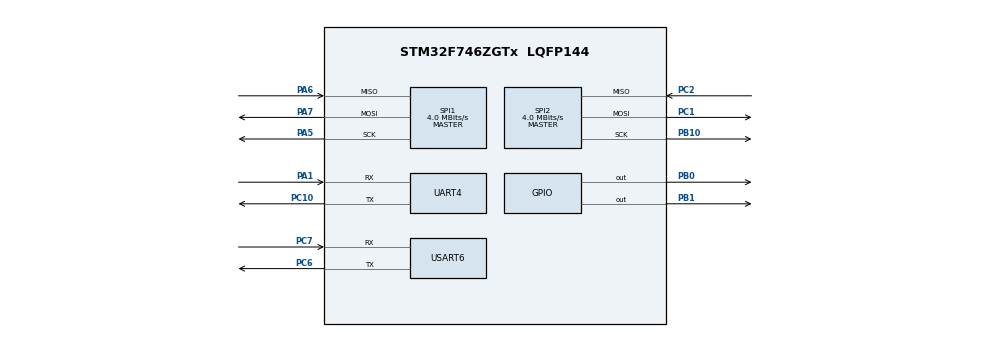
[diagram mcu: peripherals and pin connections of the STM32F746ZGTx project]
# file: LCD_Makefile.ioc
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Mcu.Family=STM32F7
Mcu.Name=STM32F746ZGTx
Mcu.Package=LQFP144
NVIC.PriorityGroup=NVIC_PRIORITYGROUP_4
PA0/WKUP.Mode=SYS_WakeUp0
PA0/WKUP.Signal=SYS_WKUP1
PA1.Mode=Asynchronous
PA1.Signal=UART4_RX
PA13.Signal=SYS_JTMS-SWDIO
PA14.Signal=SYS_JTCK-SWCLK
PA5.Mode=Full_Duplex_Master
PA5.Signal=SPI1_SCK
PA6.Mode=Full_Duplex_Master
PA6.Signal=SPI1_MISO
PA7.Mode=Full_Duplex_Master
PA7.Signal=SPI1_MOSI
PB0.Signal=GPIO_Output
PB1.Signal=GPIO_Output
PB10.Mode=Full_Duplex_Master
PB10.Signal=SPI2_SCK
PB3.Signal=SYS_JTDO-SWO
PC1.Mode=Full_Duplex_Master
PC1.Signal=SPI2_MOSI
PC10.Mode=Asynchronous
PC10.Signal=UART4_TX
PC2.Mode=Full_Duplex_Master
PC2.Signal=SPI2_MISO
PC6.Mode=Asynchronous
PC6.Signal=USART6_TX
PC7.Mode=Asynchronous
PC7.Signal=USART6_RX
ProjectManager.HeapSize=0x200
ProjectManager.StackSize=0x400
ProjectManager.TargetToolchain=SW4STM32
RCC.AHBCLKDivider=RCC_SYSCLK_DIV2
RCC.AHBFreq_Value=8000000
RCC.APB1Freq_Value=8000000
RCC.APB1TimFreq_Value=8000000
RCC.APB2Freq_Value=8000000
RCC.APB2TimFreq_Value=8000000
RCC.CortexFreq_Value=8000000
RCC.HCLKFreq_Value=8000000
RCC.HSE_VALUE=25000000
RCC.HSI_VALUE=16000000
RCC.LSE_VALUE=32768
RCC.USBFreq_Value=96000000
RCC.VCOOutputFreq_Value=192000000
SPI1.BaudRatePrescaler=SPI_BAUDRATEPRESCALER_2
SPI1.CLKPhase=SPI_PHASE_1EDGE
SPI1.CLKPolarity=SPI_POLARITY_LOW
SPI1.CalculateBaudRate=4.0 MBits/s
SPI1.DataSize=SPI_DATASIZE_8BIT
SPI1.Direction=SPI_DIRECTION_2LINES
SPI1.Mode=SPI_MODE_MASTER
SPI1.NSSPMode=SPI_NSS_PULSE_DISABLE
SPI1.VirtualType=VM_MASTER
SPI2.CalculateBaudRate=4.0 MBits/s
SPI2.DataSize=SPI_DATASIZE_8BIT
SPI2.Direction=SPI_DIRECTION_2LINES
SPI2.Mode=SPI_MODE_MASTER
SPI2.VirtualType=VM_MASTER
USART6.VirtualMode-Asynchronous=VM_ASYNC
board=custom

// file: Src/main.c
/* USER CODE BEGIN Header */
/**
  ******************************************************************************
  * @file           : main.c
  * @brief          : Main program body
  ******************************************************************************
  ** This notice applies to any and all portions of this file
  * that are not between comment pairs USER CODE BEGIN and
  * USER CODE END. Other portions of this file, whether
  * inserted by the user or by software development tools
  * are owned by their respective copyright owners.
  *
  * COPYRIGHT(c) 2019 STMicroelectronics
  *
  * Redistribution and use in source and binary forms, with or without modification,
  * are permitted provided that the following conditions are met:
  *   1. Redistributions of source code must retain the above copyright notice,
  *      this list of conditions and the following disclaimer.
  *   2. Redistributions in binary form must reproduce the above copyright notice,
  *      this list of conditions and the following disclaimer in the documentation
  *      and/or other materials provided with the distribution.
  *   3. Neither the name of STMicroelectronics nor the names of its contributors
  *      may be used to endorse or promote products derived from this software
  *      without specific prior written permission.
  *
  * THIS SOFTWARE IS PROVIDED BY THE COPYRIGHT HOLDERS AND CONTRIBUTORS "AS IS"
  * AND ANY EXPRESS OR IMPLIED WARRANTIES, INCLUDING, BUT NOT LIMITED TO, THE
  * IMPLIED WARRANTIES OF MERCHANTABILITY AND FITNESS FOR A PARTICULAR PURPOSE ARE
  * DISCLAIMED. IN NO EVENT SHALL THE COPYRIGHT HOLDER OR CONTRIBUTORS BE LIABLE
  * FOR ANY DIRECT, INDIRECT, INCIDENTAL, SPECIAL, EXEMPLARY, OR CONSEQUENTIAL
  * DAMAGES (INCLUDING, BUT NOT LIMITED TO, PROCUREMENT OF SUBSTITUTE GOODS OR
  * SERVICES; LOSS OF USE, DATA, OR PROFITS; OR BUSINESS INTERRUPTION) HOWEVER
  * CAUSED AND ON ANY THEORY OF LIABILITY, WHETHER IN CONTRACT, STRICT LIABILITY,
  * OR TORT (INCLUDING NEGLIGENCE OR OTHERWISE) ARISING IN ANY WAY OUT OF THE USE
  * OF THIS SOFTWARE, EVEN IF ADVISED OF THE POSSIBILITY OF SUCH DAMAGE.
  *
  ******************************************************************************
  */
/* USER CODE END Header */

#include "main.h"

/* USER CODE BEGIN Includes */
#include "FT_Platform.h"
#include "Ft_Esd.h"
#include "Ft_Esd_GpuAlloc.h"
/* USER CODE END Includes */

SPI_HandleTypeDef hspi1;
SPI_HandleTypeDef hspi2;

UART_HandleTypeDef huart4;
UART_HandleTypeDef huart6;

void SystemClock_Config(void);
static void MX_GPIO_Init(void);
static void MX_SPI1_Init(void);
static void MX_SPI2_Init(void);
static void MX_UART4_Init(void);
static void MX_USART6_UART_Init(void);
/* USER CODE BEGIN PFP */
extern ft_void_t FT800_BootupConfig();
/* USER CODE END PFP */

int main(void)
{

  /* MCU Configuration--------------------------------------------------------*/

  /* Reset of all peripherals, Initializes the Flash interface and the Systick. */
  HAL_Init();

  /* Configure the system clock */
  SystemClock_Config();

  /* Initialize all configured peripherals */
  MX_GPIO_Init();
  MX_SPI1_Init();
  MX_SPI2_Init();
  MX_UART4_Init();
  MX_USART6_UART_Init();
  /* USER CODE BEGIN 2 */
  FT800_BootupConfig();
  /* USER CODE END 2 */

  /* Infinite loop */
  while (1)
  {

  }
}

void SystemClock_Config(void)
{
  RCC_OscInitTypeDef RCC_OscInitStruct = {0};
  RCC_ClkInitTypeDef RCC_ClkInitStruct = {0};
  RCC_PeriphCLKInitTypeDef PeriphClkInitStruct = {0};

  /**Configure the main internal regulator output voltage
  */
  __HAL_RCC_PWR_CLK_ENABLE();
  __HAL_PWR_VOLTAGESCALING_CONFIG(PWR_REGULATOR_VOLTAGE_SCALE3);
  /**Initializes the CPU, AHB and APB busses clocks
  */
  RCC_OscInitStruct.OscillatorType = RCC_OSCILLATORTYPE_HSI;
  RCC_OscInitStruct.HSIState = RCC_HSI_ON;
  RCC_OscInitStruct.HSICalibrationValue = RCC_HSICALIBRATION_DEFAULT;
  RCC_OscInitStruct.PLL.PLLState = RCC_PLL_NONE;
  if (HAL_RCC_OscConfig(&RCC_OscInitStruct) != HAL_OK)
  {
    Error_Handler();
  }
  /**Initializes the CPU, AHB and APB busses clocks
  */
  RCC_ClkInitStruct.ClockType = RCC_CLOCKTYPE_HCLK|RCC_CLOCKTYPE_SYSCLK
                              |RCC_CLOCKTYPE_PCLK1|RCC_CLOCKTYPE_PCLK2;
  RCC_ClkInitStruct.SYSCLKSource = RCC_SYSCLKSOURCE_HSI;
  RCC_ClkInitStruct.AHBCLKDivider = RCC_SYSCLK_DIV2;
  RCC_ClkInitStruct.APB1CLKDivider = RCC_HCLK_DIV1;
  RCC_ClkInitStruct.APB2CLKDivider = RCC_HCLK_DIV1;

  if (HAL_RCC_ClockConfig(&RCC_ClkInitStruct, FLASH_LATENCY_0) != HAL_OK)
  {
    Error_Handler();
  }
  PeriphClkInitStruct.PeriphClockSelection = RCC_PERIPHCLK_USART6|RCC_PERIPHCLK_UART4;
  PeriphClkInitStruct.Uart4ClockSelection = RCC_UART4CLKSOURCE_PCLK1;
  PeriphClkInitStruct.Usart6ClockSelection = RCC_USART6CLKSOURCE_PCLK2;
  if (HAL_RCCEx_PeriphCLKConfig(&PeriphClkInitStruct) != HAL_OK)
  {
    Error_Handler();
  }
}

static void MX_SPI1_Init(void)
{

  /* SPI1 parameter configuration*/
  hspi1.Instance = SPI1;
  hspi1.Init.Mode = SPI_MODE_MASTER;
  hspi1.Init.Direction = SPI_DIRECTION_2LINES;
  hspi1.Init.DataSize = SPI_DATASIZE_8BIT;
  hspi1.Init.CLKPolarity = SPI_POLARITY_LOW;
  hspi1.Init.CLKPhase = SPI_PHASE_1EDGE;
  hspi1.Init.NSS = SPI_NSS_SOFT;
  hspi1.Init.BaudRatePrescaler = SPI_BAUDRATEPRESCALER_2;
  hspi1.Init.FirstBit = SPI_FIRSTBIT_MSB;
  hspi1.Init.TIMode = SPI_TIMODE_DISABLE;
  hspi1.Init.CRCCalculation = SPI_CRCCALCULATION_DISABLE;
  hspi1.Init.CRCPolynomial = 7;
  hspi1.Init.CRCLength = SPI_CRC_LENGTH_DATASIZE;
  hspi1.Init.NSSPMode = SPI_NSS_PULSE_DISABLE;
  if (HAL_SPI_Init(&hspi1) != HAL_OK)
  {
    Error_Handler();
  }

}

static void MX_SPI2_Init(void)
{

  /* SPI2 parameter configuration*/
  hspi2.Instance = SPI2;
  hspi2.Init.Mode = SPI_MODE_MASTER;
  hspi2.Init.Direction = SPI_DIRECTION_2LINES;
  hspi2.Init.DataSize = SPI_DATASIZE_8BIT;
  hspi2.Init.CLKPolarity = SPI_POLARITY_LOW;
  hspi2.Init.CLKPhase = SPI_PHASE_1EDGE;
  hspi2.Init.NSS = SPI_NSS_SOFT;
  hspi2.Init.BaudRatePrescaler = SPI_BAUDRATEPRESCALER_2;
  hspi2.Init.FirstBit = SPI_FIRSTBIT_MSB;
  hspi2.Init.TIMode = SPI_TIMODE_DISABLE;
  hspi2.Init.CRCCalculation = SPI_CRCCALCULATION_DISABLE;
  hspi2.Init.CRCPolynomial = 7;
  hspi2.Init.CRCLength = SPI_CRC_LENGTH_DATASIZE;
  hspi2.Init.NSSPMode = SPI_NSS_PULSE_ENABLE;
  if (HAL_SPI_Init(&hspi2) != HAL_OK)
  {
    Error_Handler();
  }

}

static void MX_UART4_Init(void)
{

  huart4.Instance = UART4;
  huart4.Init.BaudRate = 115200;
  huart4.Init.WordLength = UART_WORDLENGTH_8B;
  huart4.Init.StopBits = UART_STOPBITS_1;
  huart4.Init.Parity = UART_PARITY_NONE;
  huart4.Init.Mode = UART_MODE_TX_RX;
  huart4.Init.HwFlowCtl = UART_HWCONTROL_NONE;
  huart4.Init.OverSampling = UART_OVERSAMPLING_16;
  huart4.Init.OneBitSampling = UART_ONE_BIT_SAMPLE_DISABLE;
  huart4.AdvancedInit.AdvFeatureInit = UART_ADVFEATURE_NO_INIT;
  if (HAL_UART_Init(&huart4) != HAL_OK)
  {
    Error_Handler();
  }

}

static void MX_USART6_UART_Init(void)
{

  huart6.Instance = USART6;
  huart6.Init.BaudRate = 115200;
  huart6.Init.WordLength = UART_WORDLENGTH_8B;
  huart6.Init.StopBits = UART_STOPBITS_1;
  huart6.Init.Parity = UART_PARITY_NONE;
  huart6.Init.Mode = UART_MODE_TX_RX;
  huart6.Init.HwFlowCtl = UART_HWCONTROL_NONE;
  huart6.Init.OverSampling = UART_OVERSAMPLING_16;
  huart6.Init.OneBitSampling = UART_ONE_BIT_SAMPLE_DISABLE;
  huart6.AdvancedInit.AdvFeatureInit = UART_ADVFEATURE_NO_INIT;
  if (HAL_UART_Init(&huart6) != HAL_OK)
  {
    Error_Handler();
  }

}

static void MX_GPIO_Init(void)
{
  GPIO_InitTypeDef GPIO_InitStruct = {0};

  /* GPIO Ports Clock Enable */
  __HAL_RCC_GPIOC_CLK_ENABLE();
  __HAL_RCC_GPIOA_CLK_ENABLE();
  __HAL_RCC_GPIOB_CLK_ENABLE();

  /*Configure GPIO pin Output Level */
  HAL_GPIO_WritePin(GPIOB, GPIO_PIN_0|GPIO_PIN_1, GPIO_PIN_RESET);

  /*Configure GPIO pins : PB0 PB1 */
  GPIO_InitStruct.Pin = GPIO_PIN_0|GPIO_PIN_1;
  GPIO_InitStruct.Mode = GPIO_MODE_OUTPUT_PP;
  GPIO_InitStruct.Pull = GPIO_NOPULL;
  GPIO_InitStruct.Speed = GPIO_SPEED_FREQ_LOW;
  HAL_GPIO_Init(GPIOB, &GPIO_InitStruct);

}

void Error_Handler(void)
{
}

/************************ (C) COPYRIGHT STMicroelectronics *****END OF FILE****/
